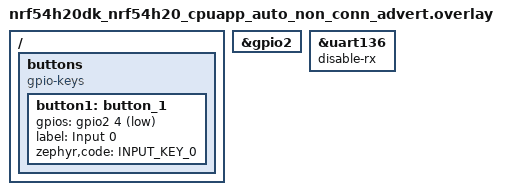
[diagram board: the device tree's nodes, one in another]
/*
 * Copyright (c) 2025 Nordic Semiconductor ASA
 *
 * SPDX-License-Identifier: LicenseRef-Nordic-5-Clause
 */

#include "nrf54h20dk_nrf54h20_cpuapp.overlay"

/ {
	/*
	 * Redefine button1 to use RXD0 - P2.04
	 * Thus, when sending character from host, there will be gpio interrupt,
	 * the same as originally triggered by sw0 button.
	 */
	buttons {
		compatible = "gpio-keys";

		button1: button_1 {
			gpios = <&gpio2 4 (GPIO_PULL_UP | GPIO_ACTIVE_LOW)>;
			label = "Input 0";
			zephyr,code = <INPUT_KEY_0>;
		};
	};
};

&gpio2 {
	status = "okay";
};

&uart136 {
	disable-rx;
};
